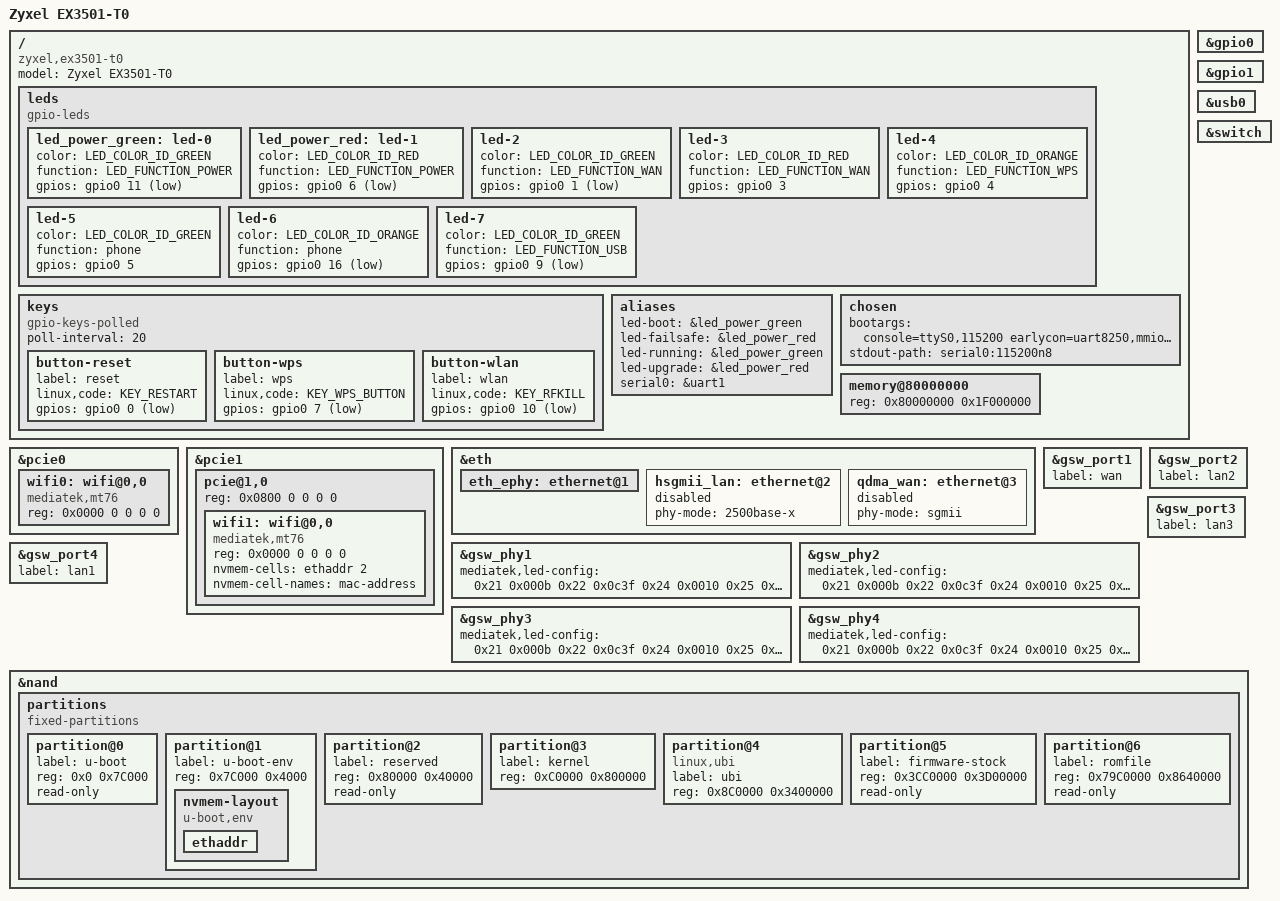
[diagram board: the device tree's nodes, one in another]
// SPDX-License-Identifier: (GPL-2.0-only OR BSD-2-Clause)
/dts-v1/;

/*
 * Zyxel EX3501-T0 (Airoha/Econet EN7523 GPON ONT/gateway).
 *
 * Derived from the device tree extracted from the running vendor firmware
 * (dtc -I fs /proc/device-tree, "real.dts"/"real.dtb") and from the vendor
 * "tclinux" firmware image, which identifies itself as:
 *   HDR2 ... "EX3501-T0-V0.6-20240620_TE"
 *
 * The vendor DT exposes many econet,ecnt-* nodes (xpon, pon_phy,
 * pon_hsgmii, sgmii, wed/wed2, gdma, i2s, pcm, crypto_k, trng,
 * thermal_phy, ...) that have NO upstream Linux binding or driver in
 * this tree yet. Those are intentionally left out here.
 *
 * USB (xHCI) and Ethernet FE/QDMA/GDM scaffolding live in the shared
 * en7523-base.dtsi (chip-wide, not board-specific). Ethernet stays
 * non-functional until the airoha_eth driver gains EN7523 match_data
 * (see comment in en7523-base.dtsi) -- WAN/LAN ethernet will not work
 * yet. USB and the two PCIe Wi-Fi radios below use generic upstream
 * drivers (mediatek,mtk-xhci, mediatek,mt76) and should work.
 *
 * Confirmed live via UART/U-Boot on real hardware (not just static
 * extraction): arch_number/machine ID 0x00001D63 (irrelevant for DT
 * boot, kept here for the record), DRAM 496 MiB at 0x80000000, U-Boot
 * env board=en7523_evb board_name=en7523_evb soc=en7523 arch=arm
 * cpu=armv7, ethaddr=xx:xx:xx:xx:xx:x0. Two DISTINCT, non-overlapping
 * addresses matter for booting a FIT image here -- conflating them
 * causes bootm to decompress the kernel on top of its own still-being-
 * read compressed data ("LZMA: uncompress or overwrite error"):
 *   - 0x81800000: where the FIT *container* is tftpboot'ed/read from.
 *   - 0x80008000: the kernel's Load Address / Entry Point inside the
 *     FIT. See the KERNEL_LOADADDR override next to this device's
 *     Device/ stanza in image/en7523.mk -- it deliberately does not
 *     use the SUBTARGET-wide 0x80200000 default either.
 *
 *     This is PHYS_OFFSET (0x80000000) + TEXT_OFFSET (0x8000), NOT
 *     the vendor FIT's own kernel entry point (0x80088000), which
 *     was tried first (real-hardware "vendor-confirmed" value) but
 *     does not hold for THIS build: our image is a raw, non-self-
 *     decompressing "Image" (U-Boot does the LZMA decompression via
 *     the FIT, not an in-kernel zImage decompressor stage), so
 *     _text/stext IS the entry point with no header/decompressor gap,
 *     and arch/arm/kernel/head.S's runtime PHYS_OFFSET auto-detection
 *     (physical address of _text, minus the fixed TEXT_OFFSET=0x8000)
 *     requires the load address to be exactly PHYS_OFFSET+TEXT_OFFSET.
 *     0x80088000 (544KB into DRAM, not 32KB) made head.S compute a
 *     PHYS_OFFSET 0x80000 too high, which a DEBUG_LL bisection tied
 *     to a hang inside __create_page_tables (identity/kernel section
 *     mapping built from that wrong base) -- confirmed on real
 *     hardware: execution reached past processor-id recognition but
 *     never returned from __create_page_tables with the old address.
 *
 *     NOTE: 0x80008000 sits INSIDE the /memreserve/ range below
 *     (0x80000000-0x80040000, the ATF footprint from real.dts). This
 *     boot chain has no live ATF/BL31 servicing SMCs in our tftpboot+
 *     bootm test setup (only a static carveout inherited from the
 *     vendor DT dump, not confirmed to be hardware-enforced during
 *     this specific test), so it's expected to be writable -- but if
 *     real hardware behaves differently here (e.g. a bus fault/hang
 *     with a different signature than before), this overlap is the
 *     first thing to revisit.
 */

/* ATF footprint measured on real hardware (real.dts atf-reserved-memory) */
/memreserve/ 0x80000000 0x40000;

#include <dt-bindings/gpio/gpio.h>
#include <dt-bindings/input/input.h>
#include <dt-bindings/leds/common.h>
#include "en7523-base.dtsi"

/ {
	/*
	 * LED map verified on the unit 2026-09-26 by toggling each SoC GPIO
	 * and watching the case (vendor userfs/led.conf gave the candidates:
	 * row = LED function, column 2 = GPIO). GPIO 27 is the USB 5 V
	 * enable and GPIO 2 the SLIC reset -- not LEDs, never listed here.
	 * No WiFi LED on SoC GPIOs (probably wired to the MT7916).
	 */
	leds {
		compatible = "gpio-leds";

		led_power_green: led-0 {
			color = <LED_COLOR_ID_GREEN>;
			function = LED_FUNCTION_POWER;
			gpios = <&gpio0 11 GPIO_ACTIVE_LOW>;
		};

		led_power_red: led-1 {
			color = <LED_COLOR_ID_RED>;
			function = LED_FUNCTION_POWER;
			gpios = <&gpio0 6 GPIO_ACTIVE_LOW>;
		};

		led-2 {
			color = <LED_COLOR_ID_GREEN>;
			function = LED_FUNCTION_WAN;
			gpios = <&gpio0 1 GPIO_ACTIVE_LOW>;
		};

		led-3 {
			color = <LED_COLOR_ID_RED>;
			function = LED_FUNCTION_WAN;
			gpios = <&gpio0 3 GPIO_ACTIVE_HIGH>;
		};

		led-4 {
			color = <LED_COLOR_ID_ORANGE>;
			function = LED_FUNCTION_WPS;
			gpios = <&gpio0 4 GPIO_ACTIVE_HIGH>;
		};

		led-5 {
			color = <LED_COLOR_ID_GREEN>;
			function = "phone";
			gpios = <&gpio0 5 GPIO_ACTIVE_HIGH>;
		};

		led-6 {
			color = <LED_COLOR_ID_ORANGE>;
			function = "phone";
			gpios = <&gpio0 16 GPIO_ACTIVE_LOW>;
		};

		led-7 {
			color = <LED_COLOR_ID_GREEN>;
			function = LED_FUNCTION_USB;
			gpios = <&gpio0 9 GPIO_ACTIVE_LOW>;
		};
	};

	/* Buttons verified 2026-09-26 (btn helper, all pull up idle, 0 when
	 * pressed): reset = GPIO 0, WPS = GPIO 7, WLAN = GPIO 10.
	 */
	/* The EN7523 GPIO controller has no interrupt support, so poll. */
	keys {
		compatible = "gpio-keys-polled";
		poll-interval = <20>;

		button-reset {
			label = "reset";
			linux,code = <KEY_RESTART>;
			gpios = <&gpio0 0 GPIO_ACTIVE_LOW>;
		};

		button-wps {
			label = "wps";
			linux,code = <KEY_WPS_BUTTON>;
			gpios = <&gpio0 7 GPIO_ACTIVE_LOW>;
		};

		button-wlan {
			label = "wlan";
			linux,code = <KEY_RFKILL>;
			gpios = <&gpio0 10 GPIO_ACTIVE_LOW>;
		};
	};

	aliases {
		led-boot = &led_power_green;
		led-failsafe = &led_power_red;
		led-running = &led_power_green;
		led-upgrade = &led_power_red;
	};
};

/ {
	model = "Zyxel EX3501-T0";
	compatible = "zyxel,ex3501-t0", "airoha,en7523";

	aliases {
		serial0 = &uart1;
	};

	/*
	 * earlycon is given an explicit uart8250,mmio32 address instead of
	 * the bare "earlycon" form. Bare earlycon depends on the kernel
	 * cmdline itself being parsed AND on of_setup_earlycon() being able
	 * to walk /chosen/stdout-path -- but U-Boot's bootm unconditionally
	 * overwrites the FDT's /chosen/bootargs with the *env* "bootargs"
	 * variable (getenv("bootargs")) if that env var is set to anything,
	 * including something that doesn't mention earlycon at all, which
	 * would silently blank this out again with zero UART output as the
	 * symptom (matches what was observed: dead silence after "Starting
	 * kernel ...", not even garbage bytes -- consistent with earlycon
	 * never being parsed at all, rather than a wrong baud/address).
	 * uart8250,mmio32 matches the uart1 node below (ns16550,
	 * reg-io-width = <4>, reg-shift = <2>) at its real physical address
	 * 0x1fbf0000, cross-checked against real.dts's serial@1fbf0000 node
	 * from the vendor firmware and against an7581.dtsi/an7583.dtsi's
	 * identical uart1 node in this tree. If UART is still silent after
	 * this, check U-Boot's own `printenv bootargs` and either `setenv
	 * bootargs` to match this line or `setenv bootargs ""` before
	 * `bootm` so U-Boot doesn't clobber the FDT's bootargs.
	 */
	chosen {
		/*
		 * earlyprintk added alongside earlycon= now that config-6.18
		 * enables CONFIG_DEBUG_LL/CONFIG_EARLY_PRINTK (same physical
		 * UART, 0x1fbf0000) -- this activates the DEBUG_LL-backed
		 * early_console for regular printk output, on top of (not a
		 * replacement for) the raw printascii/printch calls that
		 * DEBUG_LL itself makes unconditionally straight from
		 * arch/arm/kernel/head.S, before this cmdline is even parsed.
		 */
		bootargs = "console=ttyS0,115200 earlycon=uart8250,mmio32,0x1fbf0000 earlyprintk";
		stdout-path = "serial0:115200n8";
	};

	/*
	 * 496 MiB DRAM, confirmed live via U-Boot on real hardware
	 * (bdinfo/env: start 0x80000000, size 0x1F000000). Supersedes the
	 * earlier 1 GiB guess taken from real.dts memory@80000000 -- the
	 * vendor DT node apparently rounds up to a full 1 GiB and does not
	 * reflect what the bootloader actually reports as usable.
	 */
	memory@80000000 {
		device_type = "memory";
		reg = <0x80000000 0x1F000000>;
	};
};

&gpio0 {
	status = "okay";
};

&gpio1 {
	status = "okay";
};

/*
 * DIAGNOSTIC ONLY -- forces UP (cpu0-only) boot. CONFIRMED on real
 * hardware (re-tested after the unrelated KERNEL_LOADADDR/TEXT_OFFSET
 * fix, to rule PSCI in or out on its own): re-enabling en7523.dtsi's
 * psci node (compatible = "arm,psci-0.2", method = "smc") and both cpus'
 * enable-method = "psci" makes the boot hang deterministically, right
 * at "psci: probing for conduit method from DT." -- i.e. the very first
 * PSCI SMC instruction itself locks up the CPU with zero further
 * output, before any timeout or error path can run. This is NOT the
 * earlier LOADADDR-mismatch hang (that one predated any of the current
 * [DIAG]/earlycon output existing at all); this is a distinct, newly
 * confirmed dead end: this vendor's U-Boot genuinely has no working
 * PSCI/EL3 conduit, despite the upstream en7523 U-Boot series
 * referencing "ATF restrictions" elsewhere. Do not re-enable PSCI or
 * cpu1 on this board again without a different U-Boot/firmware. This
 * SoC runs UP (cpu0 only) on this device, permanently, until/unless the
 * bootloader changes.
 */
/*
 * 2026-09-26: the PSCI "hang" above was the kernel Image (TEXT_OFFSET
 * 0x8000 -> phys 0x80008000) overwriting the resident AArch32 TF-A at
 * 0x80000000-0x80040000. With TEXT_OFFSET 0x88000 / KERNEL_LOADADDR
 * 0x80088000 the monitor survives, so psci and both cores stay enabled
 * (en7523.dtsi defaults). Verified on hardware: see the git history of
 * this file if it had to be reverted.
 */

/*
 * Both PCIe root ports are enabled in the vendor DT and each carries an
 * MT7916-family Wi-Fi radio (lspci-reported PCI IDs 14c3:7906 on port 0,
 * 14c3:790a on port 1). The DT node doesn't need the PCI IDs -- mt76
 * matches on those itself -- but nvmem-cells (eeprom/mac-address) are
 * left out until the ART/factory partition layout is confirmed.
 */
&pcie0 {
	status = "okay";

	wifi0: wifi@0,0 {
		compatible = "mediatek,mt76";
		reg = <0x0000 0 0 0 0>;
	};
};

&pcie1 {
	status = "okay";

	/* The endpoint sits behind root port 0001:00:01.0 (devfn 0x08 ->
	 * reg 0x0800), so the OF node must be nested under a root-port
	 * child for the PCI core to bind it to the device; a wifi@0,0
	 * directly under the host bridge matches nothing (2026-09-26:
	 * MAC stayed the MediaTek template that way).
	 */
	pcie@1,0 {
		reg = <0x0800 0 0 0 0>;
		#address-cells = <3>;
		#size-cells = <2>;
		ranges;

		/* 14c3:7906 = the MT7916 main function (hif2 sits on pcie0) */
		wifi1: wifi@0,0 {
			compatible = "mediatek,mt76";
			reg = <0x0000 0 0 0 0>;
			nvmem-cells = <&ethaddr 2>;
			nvmem-cell-names = "mac-address";
		};
	};
};

&usb0 {
	status = "okay";
};

&eth {
	/*
	 * Experimental / iterating on real hardware -- see
	 * target/linux/airoha/patches-6.18/997-net-airoha-add-en7523-soc-data.patch
	 * for the real EN7523 match_data this needed (the driver was
	 * upstream-written for the AN7581 only; see PR #20104 discussion).
	 * With that patch and the qdma0/qdma1 reg split below, probe now
	 * gets past resource acquisition and into per-port phylink setup.
	 *
	 * Board topology: LAN via eth_ephy + hsgmii_lan, WAN via qdma_wan.
	 * Confirmed on real hardware: the WAN port on this unit is a plain
	 * RJ45 GbE jack, not PON/fiber, despite the vendor DT also carrying
	 * unused econet,ecnt-xpon/pon_phy nodes (see file header -- likely
	 * shared vendor SDK boilerplate for a GPON SKU variant).
	 *
	 * hsgmii_lan/qdma_wan (ethernet@2/@3) are deliberately left
	 * status="disabled" below. Confirmed on real hardware via the
	 * 998-diag-airoha-phylink-probe.patch DIAG prints: GDM1 (eth_ephy,
	 * phy-mode="internal") probes clean end-to-end (phylink_create
	 * ret=0), but GDM2 (ethernet@2, phy-mode="2500base-x") fails in
	 * airoha_setup_phylink() at the fwnode_phylink_pcs_parse() call
	 * with num_available_pcs=0 -- i.e. this is not a missing
	 * "pcs-handle" phandle in our DTS, there is genuinely no PCS
	 * driver/node available to reference at all: EN7523 has no
	 * upstream PCS driver (Kconfig only has PCS_AIROHA_AN7581/AN7583,
	 * no EN7523 counterpart -- see the note in en7523-base.dtsi's eth
	 * node), so even a correct pcs-handle phandle would have nothing
	 * to point at. GDM3 (ethernet@3, sgmii) takes the same PCS-requiring
	 * branch in airoha_setup_phylink() and is disabled for the same
	 * reason. Revisit once/if an EN7523 PCS driver exists upstream or
	 * locally.
	 */
	status = "okay";

	/*
	 * No nvmem-cells here on purpose: airoha_eth probes before the
	 * u-boot-env nvmem provider exists, of_get_ethdev_address() returns
	 * -EPROBE_DEFER, and the driver's error path (airoha_qdma_cleanup ->
	 * page_pool_destroy) spins forever (RCU stall, boot hangs at ~64 s,
	 * seen 2026-09-26). The LAN MAC is set from u-boot-env ethaddr in
	 * userspace instead (base-files/etc/board.d/02_network).
	 */
	eth_ephy: ethernet@1 {
		status = "okay";
	};

	/*
	 * of_get_phy_mode() (drivers/net/ethernet/airoha/airoha_eth.c,
	 * airoha_setup_phylink()) is called unconditionally for every
	 * enabled GDM port and fails probe with -EINVAL ("incorrect
	 * phy-mode") if the phy-mode property is simply absent -- it does
	 * not default to anything. Only AIROHA_GDM1_IDX (eth_ephy above)
	 * is allowed "internal"; every other port must be one of
	 * sgmii/1000base-x/2500base-x/10gbase-r/usxgmii (the interfaces
	 * airoha_setup_phylink() marks as supported for the non-GDM1 case).
	 *
	 * We have no external PHY chip info for this port (no MDIO/phy-
	 * handle confirmed) -- every real board in this tree that sets
	 * phy-mode on a non-GDM1 port does so alongside an actual
	 * phy-handle to a discrete external PHY (as21xx, en8811, ...),
	 * which we don't have. "hsgmii" itself is Airoha/MediaTek's name
	 * for a 2.5G-clocked SGMII variant -- electrically/protocol-wise
	 * the same as 2500BASE-X, and the conventional DT phy-mode value
	 * used for "hsgmii"-labeled ports across this family. Picked to
	 * get probe() past phylink setup; not confirmed against a real
	 * PHY/link-partner on this specific board yet.
	 *
	 * DISABLED: see status="disabled" note above and on qdma_wan --
	 * airoha_setup_phylink() requires a PCS for this port and EN7523
	 * has no PCS driver, confirmed on real hardware (num_available_pcs=0).
	 */
	hsgmii_lan: ethernet@2 {
		phy-mode = "2500base-x";
		status = "disabled";
	};

	/*
	 * Same of_get_phy_mode() requirement as hsgmii_lan above. This is
	 * a "virtual" GDM/QDMA-only port (no discrete external PHY known
	 * either), routed to a plain RJ45 GbE jack on real hardware (see
	 * board topology comment above) -- i.e. 1G, not multi-gig, unlike
	 * hsgmii_lan. "sgmii" is the conservative, standard 1G choice from
	 * the supported set, picked for the same reason: get probe() past
	 * phylink setup, not a confirmed hardware value.
	 *
	 * DISABLED: same PCS-less GDM2/GDM3 branch as hsgmii_lan -- see the
	 * status="disabled" note above &eth. Not tested standalone yet, but
	 * takes the identical airoha_setup_phylink() code path.
	 */
	qdma_wan: ethernet@3 {
		phy-mode = "sgmii";
		status = "disabled";
	};
};

/*
 * Embedded GSW switch (see the switch@1fb58000 comment in
 * en7523-base.dtsi for why it needs no interrupt properties and why
 * eth_ephy/GDM1 above is its CPU port, not a physical jack). All four
 * front-panel ports are enabled since it's not yet confirmed which
 * physical RJ45 jack(s) on this unit map to which gsw_portN --
 * testing on real hardware means trying the cable in each jack in
 * turn. No pinctrl/LED wiring is set (unconfirmed for this board,
 * unlike the an7581-evb reference which has real pinctrl-0/LED nodes
 * for its EVB board).
 */
&switch {
	status = "okay";
};

/* Port 0 / PHY 8 does not exist on this silicon (PMSR reads 0xdeadbeef,
 * phy_id 0, phylink validation fails) -- kept disabled. */

/* Jack labelled "WAN/LAN" on the case: switch port 1 (PHY 9). Confirmed
 * 2026-09-26 by plugging a cable in and watching eth1 carrier.
 */
&gsw_port1 {
	status = "okay";
	label = "wan";
};

&gsw_phy1 {
	status = "okay";
	/* LED0/LED1 on, blink and polarity (board LEDs are active low) */
	mediatek,led-config = <0x21 0x000b 0x22 0x0c3f 0x24 0x0010 0x25 0x0040>;
};

/* Case labels (verified 2026-09-26 by cable + carrier): LAN2 = port 2,
 * LAN3 = port 3, LAN1 = port 4, "WAN/LAN" = port 1.
 */
&gsw_port2 {
	status = "okay";
	label = "lan2";
};

&gsw_phy2 {
	status = "okay";
	/* LED0/LED1 on, blink and polarity (board LEDs are active low) */
	mediatek,led-config = <0x21 0x000b 0x22 0x0c3f 0x24 0x0010 0x25 0x0040>;
};

&gsw_port3 {
	status = "okay";
	label = "lan3";
};

&gsw_phy3 {
	status = "okay";
	/* LED0/LED1 on, blink and polarity (board LEDs are active low) */
	mediatek,led-config = <0x21 0x000b 0x22 0x0c3f 0x24 0x0010 0x25 0x0040>;
};

&gsw_port4 {
	status = "okay";
	label = "lan1";
};

&gsw_phy4 {
	status = "okay";
	/* LED0/LED1 on, blink and polarity (board LEDs are active low) */
	mediatek,led-config = <0x21 0x000b 0x22 0x0c3f 0x24 0x0010 0x25 0x0040>;
};

&nand {
	partitions {
		compatible = "fixed-partitions";
		#address-cells = <1>;
		#size-cells = <1>;

		/*
		 * Layout taken from a full dump of the 256 MiB SPI-NAND
		 * (256 KiB erase blocks, 4 KiB pages) and from the vendor
		 * U-Boot (2014.04, "flash imgread"):
		 *   0x0000000  TF-A FIP (BL2 + certs + BL31 + U-Boot as BL33)
		 *   0x0050000  Zyxel "zld" U-Boot standalone app (uImage)
		 *   0x007C000  U-Boot environment
		 *   0x00C0000  "tclinux"       firmware bank 0 (HDR2 + FIT)
		 *   0x3CC0000  "tclinux_slave" firmware bank 1 (HDR2 + FIT)
		 *   0x79C0000  vendor JFFS2 ("romfile"/config) to end of chip
		 * Each bank starts with a 0x174-byte Zyxel "HDR2" header,
		 * the FIT follows at bank + 0x174.
		 * The bootloader picks the bank with its "bootflag"
		 * (0 = bank 0, 1 = bank 1; "bootflag swap" in U-Boot).
		 */
		partition@0 {
			label = "u-boot";
			reg = <0x0 0x7C000>;
			read-only;
		};

		partition@1 {
			label = "u-boot-env";
			reg = <0x7C000 0x4000>;

			/* Standard U-Boot env (CRC32 + "name=value" list);
			 * verified on the NAND dump: ethaddr=xx:xx:xx:xx:xx:x0.
			 */
			nvmem-layout {
				compatible = "u-boot,env";

				ethaddr: ethaddr {
					#nvmem-cell-cells = <1>;
				};
			};
		};

		/* Erased on the dumped unit; kept out of the firmware bank. */
		partition@2 {
			label = "reserved";
			reg = <0x80000 0x40000>;
			read-only;
		};

		/*
		 * Vendor bank 0 ("tclinux") holds OpenWrt. The first 8 MiB is
		 * what the vendor U-Boot reads raw: HDR2 header + FIT (fdt +
		 * lzma kernel + placeholder filesystem node). The rest of the
		 * bank is UBI with the squashfs "rootfs" and "rootfs_data"
		 * volumes (JFFS2 is unusable on this SPI-NAND: on-die ECC
		 * breaks the OOB cleanmarker + data double program of a page).
		 */
		partition@3 {
			label = "kernel";
			reg = <0xC0000 0x800000>;
		};

		partition@4 {
			compatible = "linux,ubi";
			label = "ubi";
			reg = <0x8C0000 0x3400000>;
		};

		/* Vendor bank 1 ("tclinux_slave"): stock firmware, fallback. */
		partition@5 {
			label = "firmware-stock";
			reg = <0x3CC0000 0x3D00000>;
			read-only;
		};

		/* Vendor JFFS2 configuration area (romfile). */
		partition@6 {
			label = "romfile";
			reg = <0x79C0000 0x8640000>;
			read-only;
		};
	};
};
